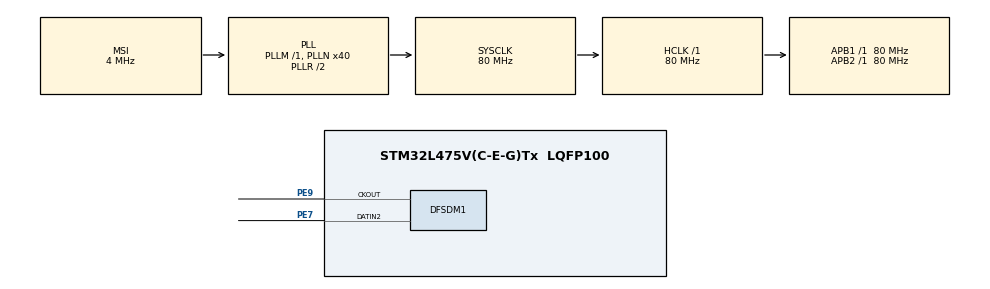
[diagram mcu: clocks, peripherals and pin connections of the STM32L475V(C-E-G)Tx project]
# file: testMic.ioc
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DFSDM1.Divider=40
DFSDM1.DmaMode_reg_FIL0=ENABLE
DFSDM1.FastMode_reg_FIL0=ENABLE
DFSDM1.Filter_regChannel_FIL0=DFSDM_CHANNEL_2
DFSDM1.Fosr_FIL0=250
DFSDM1.SincOrder_FIL0=DFSDM_FILTER_SINC3_ORDER
Dma.DFSDM1_FLT0.0.Direction=DMA_PERIPH_TO_MEMORY
Dma.DFSDM1_FLT0.0.Instance=DMA1_Channel4
Dma.DFSDM1_FLT0.0.MemDataAlignment=DMA_MDATAALIGN_WORD
Dma.DFSDM1_FLT0.0.MemInc=DMA_MINC_ENABLE
Dma.DFSDM1_FLT0.0.Mode=DMA_CIRCULAR
Dma.DFSDM1_FLT0.0.PeriphDataAlignment=DMA_PDATAALIGN_WORD
Dma.DFSDM1_FLT0.0.PeriphInc=DMA_PINC_DISABLE
Dma.DFSDM1_FLT0.0.Priority=DMA_PRIORITY_LOW
Dma.Request0=DFSDM1_FLT0
Mcu.Family=STM32L4
Mcu.Name=STM32L475V(C-E-G)Tx
Mcu.Package=LQFP100
NVIC.DMA1_Channel4_IRQn=true\:0\:0\:false\:false\:true\:false\:true\:true
NVIC.PriorityGroup=NVIC_PRIORITYGROUP_4
PE7.Signal=S_DATAIN2DFSDM1
PE9.Signal=S_CKOUTDFSDM1
ProjectManager.HeapSize=0x200
ProjectManager.StackSize=0x400
ProjectManager.TargetToolchain=STM32CubeIDE
RCC.ADCFreq_Value=48000000
RCC.AHBFreq_Value=80000000
RCC.APB1Freq_Value=80000000
RCC.APB1TimFreq_Value=80000000
RCC.APB2Freq_Value=80000000
RCC.APB2TimFreq_Value=80000000
RCC.CortexFreq_Value=80000000
RCC.HCLKFreq_Value=80000000
RCC.HSE_VALUE=8000000
RCC.HSI_VALUE=16000000
RCC.MSI_VALUE=4000000
RCC.PLLN=40
RCC.PLLSAI1N=24
RCC.SYSCLKFreq_VALUE=80000000
RCC.SYSCLKSource=RCC_SYSCLKSOURCE_PLLCLK
RCC.USBFreq_Value=48000000
RCC.VCOOutputFreq_Value=160000000
SH.S_CKOUTDFSDM1.0=DFSDM1_CKOUT,PDM_SPI_input_from_ch2_and_internal_clock
SH.S_DATAIN2DFSDM1.0=DFSDM1_DATIN2,PDM_SPI_input_from_ch2_and_internal_clock
board=B-L475E-IOT01A2

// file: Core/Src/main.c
/* USER CODE BEGIN Header */
/**
  ******************************************************************************
  * @file           : main.c
  * @brief          : Main program body
  ******************************************************************************
  * @attention
  *
  * Copyright (c) 2023 STMicroelectronics.
  * All rights reserved.
  *
  * This software is licensed under terms that can be found in the LICENSE file
  * in the root directory of this software component.
  * If no LICENSE file comes with this software, it is provided AS-IS.
  *
  ******************************************************************************
  */
/* USER CODE END Header */
#include "main.h"

DFSDM_Filter_HandleTypeDef hdfsdm1_filter0;
DFSDM_Channel_HandleTypeDef hdfsdm1_channel2;
DMA_HandleTypeDef hdma_dfsdm1_flt0;

/* USER CODE BEGIN PV */
#define AUDIO_BUF 1024
int32_t RecBuff[AUDIO_BUF];
/* USER CODE END PV */

void SystemClock_Config(void);
static void MX_GPIO_Init(void);
static void MX_DMA_Init(void);
static void MX_DFSDM1_Init(void);

int main(void)
{

  /* MCU Configuration--------------------------------------------------------*/

  /* Reset of all peripherals, Initializes the Flash interface and the Systick. */
  HAL_Init();

  /* Configure the system clock */
  SystemClock_Config();

  /* Initialize all configured peripherals */
  MX_GPIO_Init();
  MX_DMA_Init();
  MX_DFSDM1_Init();
  /* USER CODE BEGIN 2 */
  HAL_DFSDM_FilterRegularStart_DMA(&hdfsdm1_filter0, RecBuff, AUDIO_BUF);

  /* USER CODE END 2 */

  /* Infinite loop */
  while (1)
  {

  }
}

void SystemClock_Config(void)
{
  RCC_OscInitTypeDef RCC_OscInitStruct = {0};
  RCC_ClkInitTypeDef RCC_ClkInitStruct = {0};

  /** Configure the main internal regulator output voltage
  */
  if (HAL_PWREx_ControlVoltageScaling(PWR_REGULATOR_VOLTAGE_SCALE1) != HAL_OK)
  {
    Error_Handler();
  }

  /** Initializes the RCC Oscillators according to the specified parameters
  * in the RCC_OscInitTypeDef structure.
  */
  RCC_OscInitStruct.OscillatorType = RCC_OSCILLATORTYPE_MSI;
  RCC_OscInitStruct.MSIState = RCC_MSI_ON;
  RCC_OscInitStruct.MSICalibrationValue = 0;
  RCC_OscInitStruct.MSIClockRange = RCC_MSIRANGE_6;
  RCC_OscInitStruct.PLL.PLLState = RCC_PLL_ON;
  RCC_OscInitStruct.PLL.PLLSource = RCC_PLLSOURCE_MSI;
  RCC_OscInitStruct.PLL.PLLM = 1;
  RCC_OscInitStruct.PLL.PLLN = 40;
  RCC_OscInitStruct.PLL.PLLP = RCC_PLLP_DIV7;
  RCC_OscInitStruct.PLL.PLLQ = RCC_PLLQ_DIV2;
  RCC_OscInitStruct.PLL.PLLR = RCC_PLLR_DIV2;
  if (HAL_RCC_OscConfig(&RCC_OscInitStruct) != HAL_OK)
  {
    Error_Handler();
  }

  /** Initializes the CPU, AHB and APB buses clocks
  */
  RCC_ClkInitStruct.ClockType = RCC_CLOCKTYPE_HCLK|RCC_CLOCKTYPE_SYSCLK
                              |RCC_CLOCKTYPE_PCLK1|RCC_CLOCKTYPE_PCLK2;
  RCC_ClkInitStruct.SYSCLKSource = RCC_SYSCLKSOURCE_PLLCLK;
  RCC_ClkInitStruct.AHBCLKDivider = RCC_SYSCLK_DIV1;
  RCC_ClkInitStruct.APB1CLKDivider = RCC_HCLK_DIV1;
  RCC_ClkInitStruct.APB2CLKDivider = RCC_HCLK_DIV1;

  if (HAL_RCC_ClockConfig(&RCC_ClkInitStruct, FLASH_LATENCY_4) != HAL_OK)
  {
    Error_Handler();
  }
}

static void MX_DFSDM1_Init(void)
{

  hdfsdm1_filter0.Instance = DFSDM1_Filter0;
  hdfsdm1_filter0.Init.RegularParam.Trigger = DFSDM_FILTER_SW_TRIGGER;
  hdfsdm1_filter0.Init.RegularParam.FastMode = ENABLE;
  hdfsdm1_filter0.Init.RegularParam.DmaMode = ENABLE;
  hdfsdm1_filter0.Init.FilterParam.SincOrder = DFSDM_FILTER_SINC3_ORDER;
  hdfsdm1_filter0.Init.FilterParam.Oversampling = 250;
  hdfsdm1_filter0.Init.FilterParam.IntOversampling = 1;
  if (HAL_DFSDM_FilterInit(&hdfsdm1_filter0) != HAL_OK)
  {
    Error_Handler();
  }
  hdfsdm1_channel2.Instance = DFSDM1_Channel2;
  hdfsdm1_channel2.Init.OutputClock.Activation = ENABLE;
  hdfsdm1_channel2.Init.OutputClock.Selection = DFSDM_CHANNEL_OUTPUT_CLOCK_SYSTEM;
  hdfsdm1_channel2.Init.OutputClock.Divider = 40;
  hdfsdm1_channel2.Init.Input.Multiplexer = DFSDM_CHANNEL_EXTERNAL_INPUTS;
  hdfsdm1_channel2.Init.Input.DataPacking = DFSDM_CHANNEL_STANDARD_MODE;
  hdfsdm1_channel2.Init.Input.Pins = DFSDM_CHANNEL_SAME_CHANNEL_PINS;
  hdfsdm1_channel2.Init.SerialInterface.Type = DFSDM_CHANNEL_SPI_RISING;
  hdfsdm1_channel2.Init.SerialInterface.SpiClock = DFSDM_CHANNEL_SPI_CLOCK_INTERNAL;
  hdfsdm1_channel2.Init.Awd.FilterOrder = DFSDM_CHANNEL_FASTSINC_ORDER;
  hdfsdm1_channel2.Init.Awd.Oversampling = 1;
  hdfsdm1_channel2.Init.Offset = 0;
  hdfsdm1_channel2.Init.RightBitShift = 0x00;
  if (HAL_DFSDM_ChannelInit(&hdfsdm1_channel2) != HAL_OK)
  {
    Error_Handler();
  }
  if (HAL_DFSDM_FilterConfigRegChannel(&hdfsdm1_filter0, DFSDM_CHANNEL_2, DFSDM_CONTINUOUS_CONV_ON) != HAL_OK)
  {
    Error_Handler();
  }

}

static void MX_DMA_Init(void)
{

  /* DMA controller clock enable */
  __HAL_RCC_DMA1_CLK_ENABLE();

  /* DMA interrupt init */
  /* DMA1_Channel4_IRQn interrupt configuration */
  HAL_NVIC_SetPriority(DMA1_Channel4_IRQn, 0, 0);
  HAL_NVIC_EnableIRQ(DMA1_Channel4_IRQn);

}

static void MX_GPIO_Init(void)
{

  /* GPIO Ports Clock Enable */
  __HAL_RCC_GPIOE_CLK_ENABLE();

}

void Error_Handler(void)
{
  __disable_irq();
  while (1)
  {
  }
}
